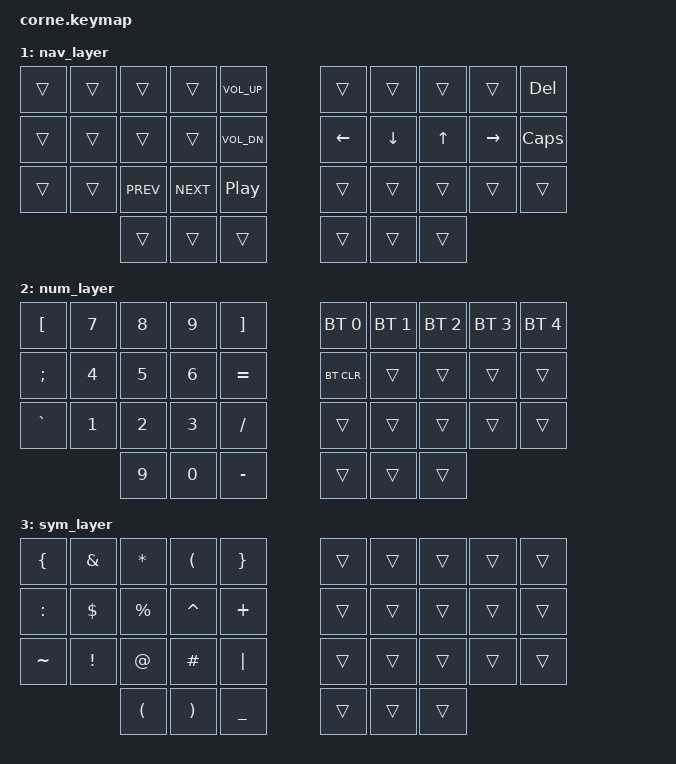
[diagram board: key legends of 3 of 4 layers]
/*
 * Copyright (c) 2020 The ZMK Contributors
 *
 * SPDX-License-Identifier: MIT
 */

#include <behaviors.dtsi>
#include <dt-bindings/zmk/keys.h>
#include <dt-bindings/zmk/bt.h>

/ {
    keymap {
        compatible = "zmk,keymap";

        default_layer {
// -----------------------------------------------------------------------------------------
// |  Q  |  W  |  F  |  P  |  G  |   |  J  |  L   |  U  |  Y  |  ;  |
// |  A  |  R  |  S  |  T  |  D  |   |  H  |  N   |  E  |  I  |  O  |
// |  Z  |  X  |  C  |  V  |  B  |   |  N  |  M   |  ,  |  .  |  /  |
//             | ESC | NAV | SFT |   | SPC | NUM  | BSPC |
            bindings = <
     &kp Q &kp W &kp F   &kp P &kp G        &kp J       &kp L &kp U     &kp Y   &kp ;
     &kp A &kp R &kp S   &kp T &kp D        &kp H       &kp N &kp E     &kp I   &kp O
     &kp Z &kp X &kp C   &kp V &kp B        &kp K       &kp M &kp COMMA &kp DOT &kp FSLH
                 &kp ESC &mo 1 &kp LSHIFT   &lt 3 SPACE &mo 2 &kp BSPC
            >;
        };
        nav_layer {
// -----------------------------------------------------------------------------------------
// |     |     |      |      | VOL UP   |   |      |      |     |       | DEL  |
// |     |     |      |      | VOL DOWN |   | LEFT | DOWN | UP  | RIGHT | CAPS |
// |     |     | PREV | NEXT | PLAY     |   |      |      |     |       |      |
//             |      |      |          |   |      |      |     |
            bindings = <
   &trans &trans &trans     &trans     &kp C_VOL_UP   &trans   &trans   &trans &trans    &kp DEL
   &trans &trans &trans     &trans     &kp C_VOL_DN   &kp LEFT &kp DOWN &kp UP &kp RIGHT &kp CAPS
   &trans &trans &kp C_PREV &kp C_NEXT &kp C_PP       &trans   &trans   &trans &trans    &trans
                               &trans &trans &trans   &trans   &trans   &trans
            >;
        };

        num_layer {
// -----------------------------------------------------------------------------------------
// |  [  |  7  |  8  |  9  |  ]  |   | BT0 | BT1 | BT2 | BT3 | BT4 |
// |  ;  |  4  |  5  |  6  |  =  |   |     |     |     |     |     |
// |  `  |  1  |  2  |  3  |  \  |   |     |     |     |     |     |
//             |  9  |  0  |  -  |   |     |     |     |
            bindings = <
   &kp LBKT  &kp N7 &kp N8 &kp N9 &kp RBKT    &bt BT_SEL 0 &bt BT_SEL 1 &bt BT_SEL 2 &bt BT_SEL 3 &bt BT_SEL 4
   &kp SEMI  &kp N4 &kp N5 &kp N6 &kp EQUAL   &bt BT_CLR   &trans       &trans       &trans       &trans
   &kp GRAVE &kp N1 &kp N2 &kp N3 &kp FSLH    &trans       &trans       &trans       &trans       &trans
                    &kp N9 &kp N0 &kp MINUS   &trans       &trans       &trans
            >;
        };

        sym_layer {
// -----------------------------------------------------------------------------------------
// |  {  |  &  |  *  |  (  |  }  |   |     |     |     |     |     |
// |  :  |  $  |  %  |  ^  |  +  |   |     |     |     |     |     |
// |  ~  |  !  |  @  |  #  |  |  |   |     |     |     |     |     |
//             |  (  |  )  |  _  |   |     |     |     |
            bindings = <
   &kp LBRC   &kp AMPS &kp ASTRK &kp LPAR  &kp RBRC    &trans &trans &trans &trans &trans
   &kp COLON  &kp DLLR &kp PRCNT &kp CARET &kp PLUS    &trans &trans &trans &trans &trans
   &kp TILDE  &kp EXCL &kp AT    &kp HASH  &kp PIPE    &trans &trans &trans &trans &trans
                       &kp LPAR  &kp RPAR  &kp UNDER   &trans &trans &trans
            >;
        };
    };
};

/ {
    combos {
        compatible = "zmk,combos";
        combo_tab {
            timeout-ms = <50>;
            key-positions = <2 3>;
            bindings = <&kp TAB>;
        };
        combo_enter {
            timeout-ms = <50>;
            key-positions = <6 7>;
            bindings = <&kp ENTER>;
        };
        combo_minus {
            timeout-ms = <50>;
            key-positions = <21 22>;
            bindings = <&kp MINUS>;
        };
        combo_colon {
            timeout-ms = <50>;
            key-positions = <26 27>;
            bindings = <&kp COLON>;
        };
        combo_underscore {
            timeout-ms = <50>;
            key-positions = <27 28>;
            bindings = <&kp UNDERSCORE>;
        };
    };
};
